AUTOSAR XML (schema 00048)
standard types defined: Boolean, SInt8, UInt16, UInt32, UInt8, boolean, uint16, uint32, uint8, sint8
package /AppNvM_SR_pkg/AppNvM_SR_dt
  11 x impl type, all with category=ARRAY:
    rt_Array_SInt8_160
      element rt_Array_SInt8_160: array-size=160, array-size-semantics=FIXED-SIZE, implementation-data-type=SInt8
    rt_Array_UInt8_128
      element rt_Array_UInt8_128: array-size=128, array-size-semantics=FIXED-SIZE, implementation-data-type=AppNvM_SR_dt/UInt8
    rt_Array_UInt8_16
      element rt_Array_UInt8_16: array-size=16, array-size-semantics=FIXED-SIZE, implementation-data-type=AppNvM_SR_dt/UInt8
    rt_Array_UInt8_17
      element rt_Array_UInt8_17: array-size=17, array-size-semantics=FIXED-SIZE, implementation-data-type=AppNvM_SR_dt/UInt8
    rt_Array_UInt8_18
      element rt_Array_UInt8_18: array-size=18, array-size-semantics=FIXED-SIZE, implementation-data-type=AppNvM_SR_dt/UInt8
    rt_Array_UInt8_240
      element rt_Array_UInt8_240: array-size=240, array-size-semantics=FIXED-SIZE, implementation-data-type=AppNvM_SR_dt/UInt8
    rt_Array_UInt8_3
      element rt_Array_UInt8_3: array-size=3, array-size-semantics=FIXED-SIZE, implementation-data-type=AppNvM_SR_dt/UInt8
    rt_Array_UInt8_4
      element rt_Array_UInt8_4: array-size=4, array-size-semantics=FIXED-SIZE, implementation-data-type=AppNvM_SR_dt/UInt8
    rt_Array_UInt8_50
      element rt_Array_UInt8_50: array-size=50, array-size-semantics=FIXED-SIZE, implementation-data-type=AppNvM_SR_dt/UInt8
    rt_Array_UInt8_6
      element rt_Array_UInt8_6: array-size=6, array-size-semantics=FIXED-SIZE, implementation-data-type=AppNvM_SR_dt/UInt8
    rt_Array_UInt8_8
      element rt_Array_UInt8_8: array-size=8, array-size-semantics=FIXED-SIZE, implementation-data-type=AppNvM_SR_dt/UInt8
package /AppNvM_SR_pkg/AppNvM_SR_if
  94 x sender receiver interface:
    gAppDiag_1809: invalidation-policy{data-element=gAppDiag_1809/Val, handle-invalid=DONT-INVALIDATE}
      data Val: sw-calibration-access=READ-ONLY, type=rt_Array_UInt8_16
    gAppDiag_1809Cnt: invalidation-policy{data-element=gAppDiag_1809Cnt/Val, handle-invalid=DONT-INVALIDATE}
      data Val: sw-calibration-access=READ-ONLY, type=AppNvM_SR_dt/UInt8
    gAppDiag_1A08: invalidation-policy{data-element=gAppDiag_1A08/Val, handle-invalid=DONT-INVALIDATE}
      data Val: type=rt_Array_UInt8_8
    gAppDiag_1A08Cnt: invalidation-policy{data-element=gAppDiag_1A08Cnt/Val, handle-invalid=DONT-INVALIDATE}
      data Val: type=AppNvM_SR_dt/UInt8
    gAppDiag_2006: invalidation-policy{data-element=gAppDiag_2006/Val, handle-invalid=DONT-INVALIDATE}
      data Val: type=rt_Array_UInt8_16
    gAppDiag_2006Cnt: invalidation-policy{data-element=gAppDiag_2006Cnt/Val, handle-invalid=DONT-INVALIDATE}
      data Val: type=AppNvM_SR_dt/UInt8
    gAppDiag_220C: invalidation-policy{data-element=gAppDiag_220C/Val, handle-invalid=DONT-INVALIDATE}
      data Val: type=rt_Array_UInt8_8
    gAppDiag_220CCnt: invalidation-policy{data-element=gAppDiag_220CCnt/Val, handle-invalid=DONT-INVALIDATE}
      data Val: type=AppNvM_SR_dt/UInt8
    gAppDiag_3206: invalidation-policy{data-element=gAppDiag_3206/Val, handle-invalid=DONT-INVALIDATE}
      data Val: sw-calibration-access=READ-ONLY, type=rt_Array_UInt8_50
    gAppDiag_3206Cnt: invalidation-policy{data-element=gAppDiag_3206Cnt/Val, handle-invalid=DONT-INVALIDATE}
      data Val: sw-calibration-access=READ-ONLY, type=AppNvM_SR_dt/UInt8
    gAppDiag_3207: invalidation-policy{data-element=gAppDiag_3207/Val, handle-invalid=DONT-INVALIDATE}
      data Val: sw-calibration-access=READ-ONLY, type=rt_Array_UInt8_50
    gAppDiag_3207Cnt: invalidation-policy{data-element=gAppDiag_3207Cnt/Val, handle-invalid=DONT-INVALIDATE}
      data Val: sw-calibration-access=READ-ONLY, type=AppNvM_SR_dt/UInt8
    gAppDiag_600A: invalidation-policy{data-element=gAppDiag_600A/Val, handle-invalid=DONT-INVALIDATE}
      data Val: type=rt_Array_UInt8_4
    gAppDiag_600ACnt: invalidation-policy{data-element=gAppDiag_600ACnt/Val, handle-invalid=DONT-INVALIDATE}
      data Val: type=AppNvM_SR_dt/UInt8
    gAppDiag_600C: invalidation-policy{data-element=gAppDiag_600C/Val, handle-invalid=DONT-INVALIDATE}
      data Val: type=AppNvM_SR_dt/UInt8
    gAppDiag_600CCnt: invalidation-policy{data-element=gAppDiag_600CCnt/Val, handle-invalid=DONT-INVALIDATE}
      data Val: type=AppNvM_SR_dt/UInt8
    gAppDiag_C300: invalidation-policy{data-element=gAppDiag_C300/Val, handle-invalid=DONT-INVALIDATE}
      data Val: sw-calibration-access=READ-ONLY, type=rt_Array_UInt8_16
    gAppDiag_C300Cnt: invalidation-policy{data-element=gAppDiag_C300Cnt/Val, handle-invalid=DONT-INVALIDATE}
      data Val: sw-calibration-access=READ-ONLY, type=AppNvM_SR_dt/UInt8
    gAppDiag_F190: invalidation-policy{data-element=gAppDiag_F190/Val, handle-invalid=DONT-INVALIDATE}
      data Val: type=rt_Array_UInt8_17
    gAppDiag_F190Cnt: invalidation-policy{data-element=gAppDiag_F190Cnt/Val, handle-invalid=DONT-INVALIDATE}
      data Val: type=AppNvM_SR_dt/UInt8
    gAppDiag_F19A: invalidation-policy{data-element=gAppDiag_F19A/Val, handle-invalid=DONT-INVALIDATE}
      data Val: sw-calibration-access=READ-ONLY, type=AppNvM_SR_dt/UInt8
    gAppDiag_F19ACnt: invalidation-policy{data-element=gAppDiag_F19ACnt/Val, handle-invalid=DONT-INVALIDATE}
      data Val: sw-calibration-access=READ-ONLY, type=AppNvM_SR_dt/UInt8
    gAppNvM_1009: invalidation-policy{data-element=gAppNvM_1009/Val, handle-invalid=DONT-INVALIDATE}
      data Val: type=AppNvM_SR_dt/rt_Array_UInt8_6
    gAppNvM_1809: invalidation-policy{data-element=gAppNvM_1809/Val, handle-invalid=DONT-INVALIDATE}
      data Val: sw-calibration-access=READ-ONLY, type=rt_Array_UInt8_16
    gAppNvM_1A08: invalidation-policy{data-element=gAppNvM_1A08/Val, handle-invalid=DONT-INVALIDATE}
      data Val: type=rt_Array_UInt8_8
    gAppNvM_2006: invalidation-policy{data-element=gAppNvM_2006/Val, handle-invalid=DONT-INVALIDATE}
      data Val: type=rt_Array_UInt8_16
    gAppNvM_220C: invalidation-policy{data-element=gAppNvM_220C/Val, handle-invalid=DONT-INVALIDATE}
      data Val: type=rt_Array_UInt8_8
    gAppNvM_3206: invalidation-policy{data-element=gAppNvM_3206/Val, handle-invalid=DONT-INVALIDATE}
      data Val: sw-calibration-access=READ-ONLY, type=rt_Array_UInt8_50
    gAppNvM_3207: invalidation-policy{data-element=gAppNvM_3207/Val, handle-invalid=DONT-INVALIDATE}
      data Val: sw-calibration-access=READ-ONLY, type=rt_Array_UInt8_50
    gAppNvM_600A: invalidation-policy{data-element=gAppNvM_600A/Val, handle-invalid=DONT-INVALIDATE}
      data Val: type=rt_Array_UInt8_4
    gAppNvM_600C: invalidation-policy{data-element=gAppNvM_600C/Val, handle-invalid=DONT-INVALIDATE}
      data Val: type=AppNvM_SR_dt/UInt8
    gAppNvM_C300: invalidation-policy{data-element=gAppNvM_C300/Val, handle-invalid=DONT-INVALIDATE}
      data Val: sw-calibration-access=READ-ONLY, type=rt_Array_UInt8_16
    gAppNvM_F190: invalidation-policy{data-element=gAppNvM_F190/Val, handle-invalid=DONT-INVALIDATE}
      data Val: type=rt_Array_UInt8_17
    gAppNvM_F19A: invalidation-policy{data-element=gAppNvM_F19A/Val, handle-invalid=DONT-INVALIDATE}
      data Val: sw-calibration-access=READ-ONLY, type=AppNvM_SR_dt/UInt8
    gEDH_u16RLDoorHandleBigPosition: invalidation-policy{data-element=gEDH_u16RLDoorHandleBigPosition/Val, handle-invalid=DONT-INVALIDATE}
      data Val: sw-calibration-access=READ-ONLY, type=UInt16
    gEDH_u16RLDoorHandlePosition: invalidation-policy{data-element=gEDH_u16RLDoorHandlePosition/Val, handle-invalid=DONT-INVALIDATE}
      data Val: sw-calibration-access=READ-ONLY, type=UInt16
    gEDH_u16RLDoorHandleSmallPosition: invalidation-policy{data-element=gEDH_u16RLDoorHandleSmallPosition/Val, handle-invalid=DONT-INVALIDATE}
      data Val: sw-calibration-access=READ-ONLY, type=UInt16
    gEDH_u16RRDoorHandleBigPosition: invalidation-policy{data-element=gEDH_u16RRDoorHandleBigPosition/Val, handle-invalid=DONT-INVALIDATE}
      data Val: sw-calibration-access=READ-ONLY, type=UInt16
    gEDH_u16RRDoorHandlePosition: invalidation-policy{data-element=gEDH_u16RRDoorHandlePosition/Val, handle-invalid=DONT-INVALIDATE}
      data Val: sw-calibration-access=READ-ONLY, type=UInt16
    gEDH_u16RRDoorHandleSmallPosition: invalidation-policy{data-element=gEDH_u16RRDoorHandleSmallPosition/Val, handle-invalid=DONT-INVALIDATE}
      data Val: sw-calibration-access=READ-ONLY, type=UInt16
    gEDH_u8RLDoorHandleBigPositionWrtCnt: invalidation-policy{data-element=gEDH_u8RLDoorHandleBigPositionWrtCnt/Val, handle-invalid=DONT-INVALIDATE}
      data Val: sw-calibration-access=READ-ONLY, type=AppNvM_SR_dt/UInt8
    gEDH_u8RLDoorHandlePositionWrtCnt: invalidation-policy{data-element=gEDH_u8RLDoorHandlePositionWrtCnt/Val, handle-invalid=DONT-INVALIDATE}
      data Val: sw-calibration-access=READ-ONLY, type=AppNvM_SR_dt/UInt8
    gEDH_u8RLDoorHandleSmallPositionWrtCnt: invalidation-policy{data-element=gEDH_u8RLDoorHandleSmallPositionWrtCnt/Val, handle-invalid=DONT-INVALIDATE}
      data Val: sw-calibration-access=READ-ONLY, type=AppNvM_SR_dt/UInt8
    gEDH_u8RRDoorHandleBigPositionWrtCnt: invalidation-policy{data-element=gEDH_u8RRDoorHandleBigPositionWrtCnt/Val, handle-invalid=DONT-INVALIDATE}
      data Val: sw-calibration-access=READ-ONLY, type=AppNvM_SR_dt/UInt8
    gEDH_u8RRDoorHandlePositionWrtCnt: invalidation-policy{data-element=gEDH_u8RRDoorHandlePositionWrtCnt/Val, handle-invalid=DONT-INVALIDATE}
      data Val: sw-calibration-access=READ-ONLY, type=AppNvM_SR_dt/UInt8
    gEDH_u8RRDoorHandleSmallPositionWrtCnt: invalidation-policy{data-element=gEDH_u8RRDoorHandleSmallPositionWrtCnt/Val, handle-invalid=DONT-INVALIDATE}
      data Val: sw-calibration-access=READ-ONLY, type=AppNvM_SR_dt/UInt8
    gEPB_u8PbcoutDataStorageArea1WrtCnt: invalidation-policy{data-element=gEPB_u8PbcoutDataStorageArea1WrtCnt/Val, handle-invalid=DONT-INVALIDATE}
      data Val: sw-calibration-access=READ-ONLY, type=AppNvM_SR_dt/UInt8
    gEPB_u8PbcoutDataStorageArea2WrtCnt: invalidation-policy{data-element=gEPB_u8PbcoutDataStorageArea2WrtCnt/Val, handle-invalid=DONT-INVALIDATE}
      data Val: sw-calibration-access=READ-ONLY, type=AppNvM_SR_dt/UInt8
    gEPB_u8PbcoutDataStorageArea3WrtCnt: invalidation-policy{data-element=gEPB_u8PbcoutDataStorageArea3WrtCnt/Val, handle-invalid=DONT-INVALIDATE}
      data Val: sw-calibration-access=READ-ONLY, type=AppNvM_SR_dt/UInt8
    gEPB_u8PbcoutDataStorageWriteArea1_a: invalidation-policy{data-element=gEPB_u8PbcoutDataStorageWriteArea1_a/Val, handle-invalid=DONT-INVALIDATE}
      data Val: sw-calibration-access=READ-ONLY, type=rt_Array_UInt8_8
    gEPB_u8PbcoutDataStorageWriteArea2_a: invalidation-policy{data-element=gEPB_u8PbcoutDataStorageWriteArea2_a/Val, handle-invalid=DONT-INVALIDATE}
      data Val: sw-calibration-access=READ-ONLY, type=rt_Array_UInt8_8
    gEPB_u8PbcoutDataStorageWriteArea3_a: invalidation-policy{data-element=gEPB_u8PbcoutDataStorageWriteArea3_a/Val, handle-invalid=DONT-INVALIDATE}
      data Val: sw-calibration-access=READ-ONLY, type=rt_Array_UInt8_240
    gEPB_u8SsmoutDataStorageWrite_a: invalidation-policy{data-element=gEPB_u8SsmoutDataStorageWrite_a/Val, handle-invalid=DONT-INVALIDATE}
      data Val: sw-calibration-access=READ-ONLY, type=rt_Array_UInt8_128
    gEPB_u8SsmoutDataStorageWrtCnt: invalidation-policy{data-element=gEPB_u8SsmoutDataStorageWrtCnt/Val, handle-invalid=DONT-INVALIDATE}
      data Val: sw-calibration-access=READ-ONLY, type=AppNvM_SR_dt/UInt8
    gNVM_au8SlcEepBlock_RR: invalidation-policy{data-element=gNVM_au8SlcEepBlock_RR/Val, handle-invalid=DONT-INVALIDATE}
      data Val: type=rt_Array_SInt8_160
    gNVM_au8SlcEepBlock2_RR: invalidation-policy{data-element=gNVM_au8SlcEepBlock2_RR/Val, handle-invalid=DONT-INVALIDATE}
      data Val: type=rt_Array_UInt8_18
    gNVM_bPbcinDataStorageValid1: invalidation-policy{data-element=gNVM_bPbcinDataStorageValid1/Val, handle-invalid=DONT-INVALIDATE}
      data Val: sw-calibration-access=READ-ONLY, type=Boolean
    gNVM_bPbcinDataStorageValid2: invalidation-policy{data-element=gNVM_bPbcinDataStorageValid2/Val, handle-invalid=DONT-INVALIDATE}
      data Val: sw-calibration-access=READ-ONLY, type=Boolean
    gNVM_bPbcinDataStorageValid3: invalidation-policy{data-element=gNVM_bPbcinDataStorageValid3/Val, handle-invalid=DONT-INVALIDATE}
      data Val: sw-calibration-access=READ-ONLY, type=Boolean
    gNVM_bRLTPflg: invalidation-policy{data-element=gNVM_bRLTPflg/Val, handle-invalid=DONT-INVALIDATE}
      data Val: type=Boolean
    gNVM_bRRTPflg: invalidation-policy{data-element=gNVM_bRRTPflg/Val, handle-invalid=DONT-INVALIDATE}
      data Val: type=Boolean
    gNVM_bSsminDataStorageValid: invalidation-policy{data-element=gNVM_bSsminDataStorageValid/Val, handle-invalid=DONT-INVALIDATE}
      data Val: sw-calibration-access=READ-ONLY, type=Boolean
    gNVM_s8SlcEepBlock_FRL: invalidation-policy{data-element=gNVM_s8SlcEepBlock_FRL/Val, handle-invalid=DONT-INVALIDATE}
      data Val: type=rt_Array_SInt8_160
    gNVM_u16RLDoorHandleBigPosition: invalidation-policy{data-element=gNVM_u16RLDoorHandleBigPosition/Val, handle-invalid=DONT-INVALIDATE}
      data Val: sw-calibration-access=READ-ONLY, type=UInt16
    gNVM_u16RLDoorHandlePosition: invalidation-policy{data-element=gNVM_u16RLDoorHandlePosition/Val, handle-invalid=DONT-INVALIDATE}
      data Val: sw-calibration-access=READ-ONLY, type=UInt16
    gNVM_u16RLDoorHandleSmallPosition: invalidation-policy{data-element=gNVM_u16RLDoorHandleSmallPosition/Val, handle-invalid=DONT-INVALIDATE}
      data Val: sw-calibration-access=READ-ONLY, type=UInt16
    gNVM_u16RRDoorHandleBigPosition: invalidation-policy{data-element=gNVM_u16RRDoorHandleBigPosition/Val, handle-invalid=DONT-INVALIDATE}
      data Val: sw-calibration-access=READ-ONLY, type=UInt16
    gNVM_u16RRDoorHandlePosition: invalidation-policy{data-element=gNVM_u16RRDoorHandlePosition/Val, handle-invalid=DONT-INVALIDATE}
      data Val: sw-calibration-access=READ-ONLY, type=UInt16
    gNVM_u16RRDoorHandleSmallPosition: invalidation-policy{data-element=gNVM_u16RRDoorHandleSmallPosition/Val, handle-invalid=DONT-INVALIDATE}
      data Val: sw-calibration-access=READ-ONLY, type=UInt16
    gNVM_u32RLMotorTemperature: invalidation-policy{data-element=gNVM_u32RLMotorTemperature/Val, handle-invalid=DONT-INVALIDATE}
      data Val: type=UInt32
    gNVM_u32RRMotorTemperature: invalidation-policy{data-element=gNVM_u32RRMotorTemperature/Val, handle-invalid=DONT-INVALIDATE}
      data Val: type=UInt32
    gNVM_u8FvMTripCntBlock: invalidation-policy{data-element=gNVM_u8FvMTripCntBlock/Val, handle-invalid=DONT-INVALIDATE}
      data Val: type=rt_Array_UInt8_4
    gNVM_u8PbcinDataStorageReadArea1_a: invalidation-policy{data-element=gNVM_u8PbcinDataStorageReadArea1_a/Val, handle-invalid=DONT-INVALIDATE}
      data Val: sw-calibration-access=READ-ONLY, type=rt_Array_UInt8_8
    gNVM_u8PbcinDataStorageReadArea2_a: invalidation-policy{data-element=gNVM_u8PbcinDataStorageReadArea2_a/Val, handle-invalid=DONT-INVALIDATE}
      data Val: sw-calibration-access=READ-ONLY, type=rt_Array_UInt8_8
    gNVM_u8PbcinDataStorageReadArea3_a: invalidation-policy{data-element=gNVM_u8PbcinDataStorageReadArea3_a/Val, handle-invalid=DONT-INVALIDATE}
      data Val: sw-calibration-access=READ-ONLY, type=rt_Array_UInt8_240
    gNVM_u8SecOCBlock: invalidation-policy{data-element=gNVM_u8SecOCBlock/Val, handle-invalid=DONT-INVALIDATE}
      data Val: type=rt_Array_UInt8_3
    gNVM_u8SlcEepBlock2_FRL: invalidation-policy{data-element=gNVM_u8SlcEepBlock2_FRL/Val, handle-invalid=DONT-INVALIDATE}
      data Val: type=rt_Array_UInt8_18
    gNVM_u8SsminDataStorageRead_a: invalidation-policy{data-element=gNVM_u8SsminDataStorageRead_a/Val, handle-invalid=DONT-INVALIDATE}
      data Val: sw-calibration-access=READ-ONLY, type=rt_Array_UInt8_128
    gSLC_s8SlcEepBlock_FRL: invalidation-policy{data-element=gSLC_s8SlcEepBlock_FRL/Val, handle-invalid=DONT-INVALIDATE}
      data Val: type=rt_Array_SInt8_160
    gSLC_s8SlcEepBlock_RR: invalidation-policy{data-element=gSLC_s8SlcEepBlock_RR/Val, handle-invalid=DONT-INVALIDATE}
      data Val: type=rt_Array_SInt8_160
    gSLC_u8FRLEEWrtCnt: invalidation-policy{data-element=gSLC_u8FRLEEWrtCnt/Val, handle-invalid=DONT-INVALIDATE}
      data Val: type=AppNvM_SR_dt/UInt8
    gSLC_u8FRLEEWrtCnt2: invalidation-policy{data-element=gSLC_u8FRLEEWrtCnt2/Val, handle-invalid=DONT-INVALIDATE}
      data Val: type=AppNvM_SR_dt/UInt8
    gSLC_u8RREEWrtCnt: invalidation-policy{data-element=gSLC_u8RREEWrtCnt/Val, handle-invalid=DONT-INVALIDATE}
      data Val: type=AppNvM_SR_dt/UInt8
    gSLC_u8RREEWrtCnt2: invalidation-policy{data-element=gSLC_u8RREEWrtCnt2/Val, handle-invalid=DONT-INVALIDATE}
      data Val: type=AppNvM_SR_dt/UInt8
    gSLC_u8SlcEepBlock2_FRL: invalidation-policy{data-element=gSLC_u8SlcEepBlock2_FRL/Val, handle-invalid=DONT-INVALIDATE}
      data Val: type=rt_Array_UInt8_18
    gSLC_u8SlcEepBlock2_RR: invalidation-policy{data-element=gSLC_u8SlcEepBlock2_RR/Val, handle-invalid=DONT-INVALIDATE}
      data Val: type=rt_Array_UInt8_18
    gUxFvM_u8FvMTripCntBlock: invalidation-policy{data-element=gUxFvM_u8FvMTripCntBlock/Val, handle-invalid=DONT-INVALIDATE}
      data Val: type=rt_Array_UInt8_4
    gUxFvM_u8FvMTripCntBlockWrtCnt: invalidation-policy{data-element=gUxFvM_u8FvMTripCntBlockWrtCnt/Val, handle-invalid=DONT-INVALIDATE}
      data Val: type=AppNvM_SR_dt/UInt8
    gUxSecOC_u8SecOCBlock: invalidation-policy{data-element=gUxSecOC_u8SecOCBlock/Val, handle-invalid=DONT-INVALIDATE}
      data Val: type=rt_Array_UInt8_3
    gUxSecOC_u8SecOCBlockWrtCnt: invalidation-policy{data-element=gUxSecOC_u8SecOCBlockWrtCnt/Val, handle-invalid=DONT-INVALIDATE}
      data Val: type=AppNvM_SR_dt/UInt8
    gWND_bRLTPflg: invalidation-policy{data-element=gWND_bRLTPflg/Val, handle-invalid=DONT-INVALIDATE}
      data Val: type=Boolean
    gWND_bRRTPflg: invalidation-policy{data-element=gWND_bRRTPflg/Val, handle-invalid=DONT-INVALIDATE}
      data Val: type=Boolean
    gWND_u32RLMotorTemperature: invalidation-policy{data-element=gWND_u32RLMotorTemperature/Val, handle-invalid=DONT-INVALIDATE}
      data Val: type=UInt32
    gWND_u32RRMotorTemperature: invalidation-policy{data-element=gWND_u32RRMotorTemperature/Val, handle-invalid=DONT-INVALIDATE}
      data Val: type=UInt32
package /AppNvM_SR_pkg/AppNvM_SR_swc
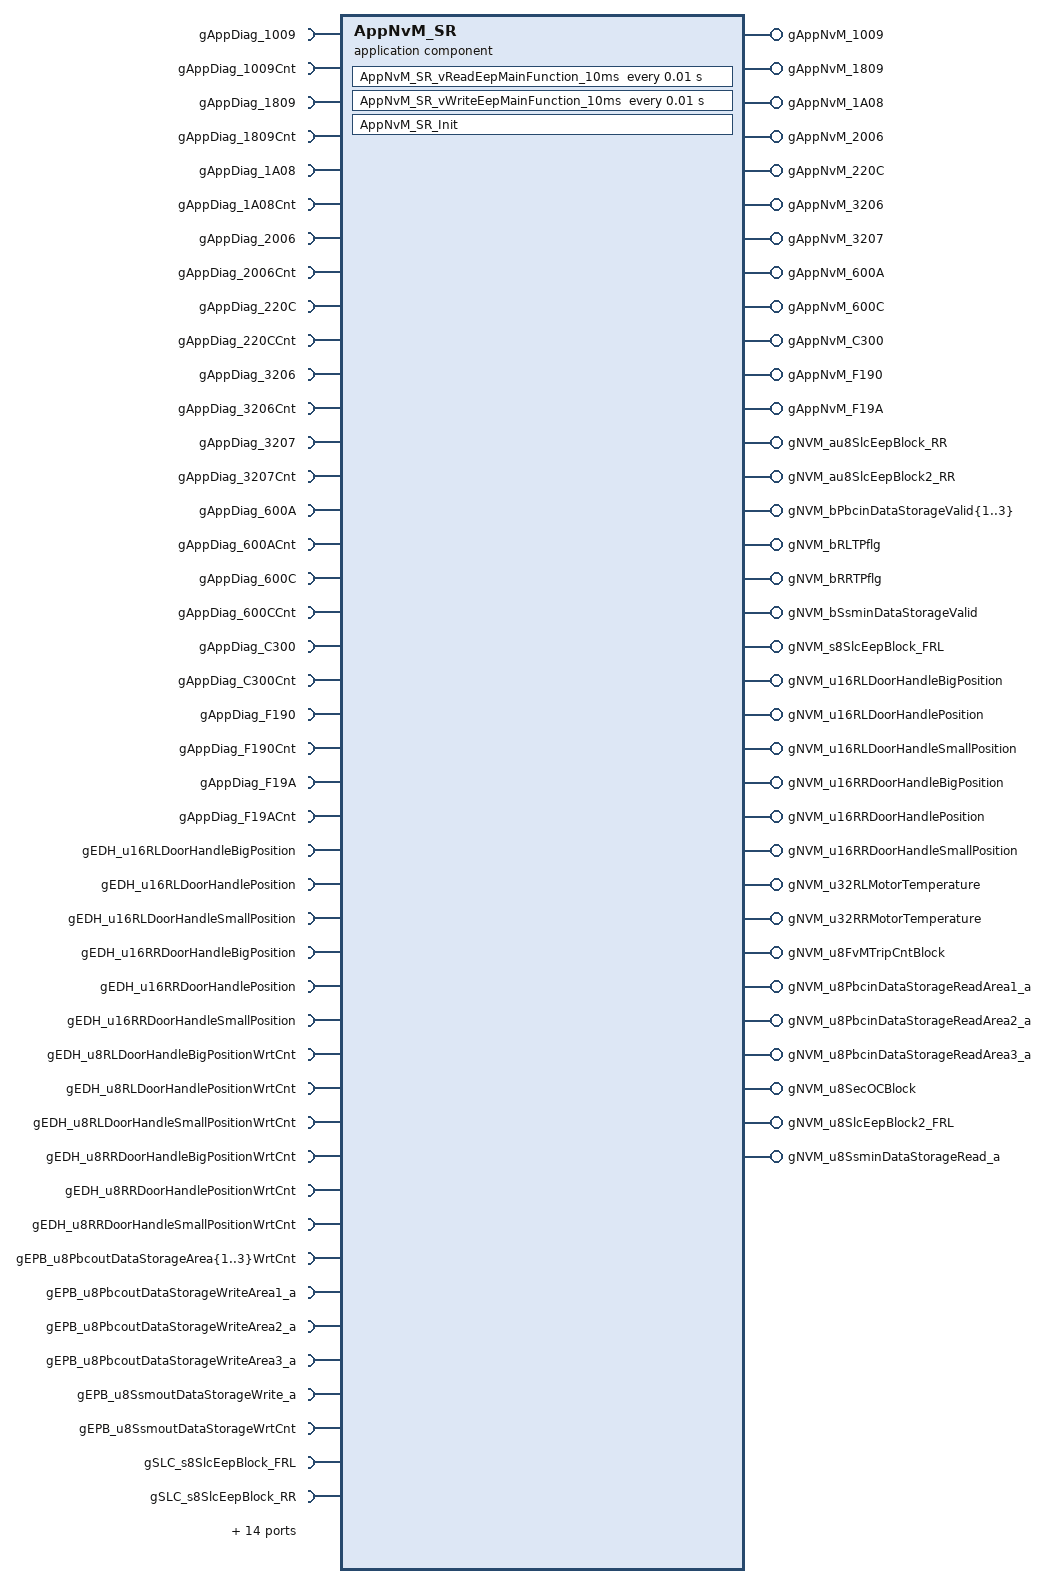
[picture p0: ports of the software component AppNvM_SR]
  application sw component type AppNvM_SR
    36 x provide port:
      gAppNvM_1009: nonqueued-sender-com-spec{data-element=gAppNvM_1009/Val, init-value=6 x 0}, provided-interface=gAppNvM_1009
      gAppNvM_1809: nonqueued-sender-com-spec{data-element=gAppNvM_1809/Val, init-value=16 x 0}, provided-interface=gAppNvM_1809
      gAppNvM_1A08: nonqueued-sender-com-spec{data-element=gAppNvM_1A08/Val, init-value=8 x 0}, provided-interface=gAppNvM_1A08
      gAppNvM_2006: nonqueued-sender-com-spec{data-element=gAppNvM_2006/Val, init-value=16 x 0}, provided-interface=gAppNvM_2006
      gAppNvM_220C: nonqueued-sender-com-spec{data-element=gAppNvM_220C/Val, init-value=8 x 0}, provided-interface=gAppNvM_220C
      gAppNvM_3206: nonqueued-sender-com-spec{data-element=gAppNvM_3206/Val, init-value=50 x 0}, provided-interface=gAppNvM_3206
      gAppNvM_3207: nonqueued-sender-com-spec{data-element=gAppNvM_3207/Val, init-value=50 x 0}, provided-interface=gAppNvM_3207
      gAppNvM_600A: nonqueued-sender-com-spec{data-element=gAppNvM_600A/Val, init-value=[0, 0, 0, 0]}, provided-interface=gAppNvM_600A
      gAppNvM_600C: nonqueued-sender-com-spec{data-element=gAppNvM_600C/Val, init-value=0}, provided-interface=gAppNvM_600C
      gAppNvM_C300: nonqueued-sender-com-spec{data-element=gAppNvM_C300/Val, init-value=16 x 0}, provided-interface=gAppNvM_C300
      gAppNvM_F190: nonqueued-sender-com-spec{data-element=gAppNvM_F190/Val, init-value=17 x 0}, provided-interface=gAppNvM_F190
      gAppNvM_F19A: nonqueued-sender-com-spec{data-element=gAppNvM_F19A/Val, init-value=0}, provided-interface=gAppNvM_F19A
      gNVM_au8SlcEepBlock_RR: nonqueued-sender-com-spec{data-element=gNVM_au8SlcEepBlock_RR/Val, init-value=160 x 0}, provided-interface=gNVM_au8SlcEepBlock_RR
      gNVM_au8SlcEepBlock2_RR: nonqueued-sender-com-spec{data-element=gNVM_au8SlcEepBlock2_RR/Val, init-value=18 x 0}, provided-interface=gNVM_au8SlcEepBlock2_RR
      gNVM_bPbcinDataStorageValid{1..3}: nonqueued-sender-com-spec{data-element=gNVM_bPbcinDataStorageValid{1..3}/Val, init-value=0}, provided-interface=gNVM_bPbcinDataStorageValid{1..3}
      gNVM_bRLTPflg: nonqueued-sender-com-spec{data-element=gNVM_bRLTPflg/Val, init-value=0}, provided-interface=gNVM_bRLTPflg
      gNVM_bRRTPflg: nonqueued-sender-com-spec{data-element=gNVM_bRRTPflg/Val, init-value=0}, provided-interface=gNVM_bRRTPflg
      gNVM_bSsminDataStorageValid: nonqueued-sender-com-spec{data-element=gNVM_bSsminDataStorageValid/Val, init-value=0}, provided-interface=gNVM_bSsminDataStorageValid
      gNVM_s8SlcEepBlock_FRL: nonqueued-sender-com-spec{data-element=gNVM_s8SlcEepBlock_FRL/Val, init-value=160 x 0}, provided-interface=gNVM_s8SlcEepBlock_FRL
      gNVM_u16RLDoorHandleBigPosition: nonqueued-sender-com-spec{data-element=gNVM_u16RLDoorHandleBigPosition/Val, init-value=65535}, provided-interface=gNVM_u16RLDoorHandleBigPosition
      gNVM_u16RLDoorHandlePosition: nonqueued-sender-com-spec{data-element=gNVM_u16RLDoorHandlePosition/Val, init-value=32767}, provided-interface=gNVM_u16RLDoorHandlePosition
      gNVM_u16RLDoorHandleSmallPosition: nonqueued-sender-com-spec{data-element=gNVM_u16RLDoorHandleSmallPosition/Val, init-value=0}, provided-interface=gNVM_u16RLDoorHandleSmallPosition
      gNVM_u16RRDoorHandleBigPosition: nonqueued-sender-com-spec{data-element=gNVM_u16RRDoorHandleBigPosition/Val, init-value=65535}, provided-interface=gNVM_u16RRDoorHandleBigPosition
      gNVM_u16RRDoorHandlePosition: nonqueued-sender-com-spec{data-element=gNVM_u16RRDoorHandlePosition/Val, init-value=32767}, provided-interface=gNVM_u16RRDoorHandlePosition
      gNVM_u16RRDoorHandleSmallPosition: nonqueued-sender-com-spec{data-element=gNVM_u16RRDoorHandleSmallPosition/Val, init-value=0}, provided-interface=gNVM_u16RRDoorHandleSmallPosition
      gNVM_u32RLMotorTemperature: nonqueued-sender-com-spec{data-element=gNVM_u32RLMotorTemperature/Val, init-value=0}, provided-interface=gNVM_u32RLMotorTemperature
      gNVM_u32RRMotorTemperature: nonqueued-sender-com-spec{data-element=gNVM_u32RRMotorTemperature/Val, init-value=0}, provided-interface=gNVM_u32RRMotorTemperature
      gNVM_u8FvMTripCntBlock: nonqueued-sender-com-spec{data-element=gNVM_u8FvMTripCntBlock/Val, init-value=[0, 0, 0, 0]}, provided-interface=gNVM_u8FvMTripCntBlock
      gNVM_u8PbcinDataStorageReadArea1_a: nonqueued-sender-com-spec{data-element=gNVM_u8PbcinDataStorageReadArea1_a/Val, init-value=8 x 255}, provided-interface=gNVM_u8PbcinDataStorageReadArea1_a
      gNVM_u8PbcinDataStorageReadArea2_a: nonqueued-sender-com-spec{data-element=gNVM_u8PbcinDataStorageReadArea2_a/Val, init-value=8 x 255}, provided-interface=gNVM_u8PbcinDataStorageReadArea2_a
      gNVM_u8PbcinDataStorageReadArea3_a: nonqueued-sender-com-spec{data-element=gNVM_u8PbcinDataStorageReadArea3_a/Val, init-value=240 x 255}, provided-interface=gNVM_u8PbcinDataStorageReadArea3_a
      gNVM_u8SecOCBlock: nonqueued-sender-com-spec{data-element=gNVM_u8SecOCBlock/Val, init-value=[0, 0, 255]}, provided-interface=gNVM_u8SecOCBlock
      gNVM_u8SlcEepBlock2_FRL: nonqueued-sender-com-spec{data-element=gNVM_u8SlcEepBlock2_FRL/Val, init-value=18 x 0}, provided-interface=gNVM_u8SlcEepBlock2_FRL
      gNVM_u8SsminDataStorageRead_a: nonqueued-sender-com-spec{data-element=gNVM_u8SsminDataStorageRead_a/Val, init-value=128 x 255}, provided-interface=gNVM_u8SsminDataStorageRead_a
    60 x require port:
      gAppDiag_1009: nonqueued-receiver-com-spec{data-element=gAppDiag_1009/Val, filter=data-filter-type=ALWAYS, init-value=6 x 0}, required-interface=gAppDiag_1009
      gAppDiag_1009Cnt: nonqueued-receiver-com-spec{data-element=gAppDiag_1009Cnt/Val, filter=data-filter-type=ALWAYS, init-value=0}, required-interface=gAppDiag_1009Cnt
      gAppDiag_1809: nonqueued-receiver-com-spec{data-element=gAppDiag_1809/Val, filter=data-filter-type=ALWAYS, init-value=16 x 0}, required-interface=gAppDiag_1809
      gAppDiag_1809Cnt: nonqueued-receiver-com-spec{data-element=gAppDiag_1809Cnt/Val, filter=data-filter-type=ALWAYS, init-value=0}, required-interface=gAppDiag_1809Cnt
      gAppDiag_1A08: nonqueued-receiver-com-spec{data-element=gAppDiag_1A08/Val, filter=data-filter-type=ALWAYS, init-value=8 x 0}, required-interface=gAppDiag_1A08
      gAppDiag_1A08Cnt: nonqueued-receiver-com-spec{data-element=gAppDiag_1A08Cnt/Val, filter=data-filter-type=ALWAYS, init-value=0}, required-interface=gAppDiag_1A08Cnt
      gAppDiag_2006: nonqueued-receiver-com-spec{data-element=gAppDiag_2006/Val, filter=data-filter-type=ALWAYS, init-value=16 x 0}, required-interface=gAppDiag_2006
      gAppDiag_2006Cnt: nonqueued-receiver-com-spec{data-element=gAppDiag_2006Cnt/Val, filter=data-filter-type=ALWAYS, init-value=0}, required-interface=gAppDiag_2006Cnt
      gAppDiag_220C: nonqueued-receiver-com-spec{data-element=gAppDiag_220C/Val, filter=data-filter-type=ALWAYS, init-value=8 x 0}, required-interface=gAppDiag_220C
      gAppDiag_220CCnt: nonqueued-receiver-com-spec{data-element=gAppDiag_220CCnt/Val, filter=data-filter-type=ALWAYS, init-value=0}, required-interface=gAppDiag_220CCnt
      gAppDiag_3206: nonqueued-receiver-com-spec{data-element=gAppDiag_3206/Val, filter=data-filter-type=ALWAYS, init-value=50 x 0}, required-interface=gAppDiag_3206
      gAppDiag_3206Cnt: nonqueued-receiver-com-spec{data-element=gAppDiag_3206Cnt/Val, filter=data-filter-type=ALWAYS, init-value=0}, required-interface=gAppDiag_3206Cnt
      gAppDiag_3207: nonqueued-receiver-com-spec{data-element=gAppDiag_3207/Val, filter=data-filter-type=ALWAYS, init-value=50 x 0}, required-interface=gAppDiag_3207
      gAppDiag_3207Cnt: nonqueued-receiver-com-spec{data-element=gAppDiag_3207Cnt/Val, filter=data-filter-type=ALWAYS, init-value=0}, required-interface=gAppDiag_3207Cnt
      gAppDiag_600A: nonqueued-receiver-com-spec{data-element=gAppDiag_600A/Val, filter=data-filter-type=ALWAYS, init-value=[0, 0, 0, 0]}, required-interface=gAppDiag_600A
      gAppDiag_600ACnt: nonqueued-receiver-com-spec{data-element=gAppDiag_600ACnt/Val, filter=data-filter-type=ALWAYS, init-value=0}, required-interface=gAppDiag_600ACnt
      gAppDiag_600C: nonqueued-receiver-com-spec{data-element=gAppDiag_600C/Val, filter=data-filter-type=ALWAYS, init-value=0}, required-interface=gAppDiag_600C
      gAppDiag_600CCnt: nonqueued-receiver-com-spec{data-element=gAppDiag_600CCnt/Val, filter=data-filter-type=ALWAYS, init-value=0}, required-interface=gAppDiag_600CCnt
      gAppDiag_C300: nonqueued-receiver-com-spec{data-element=gAppDiag_C300/Val, filter=data-filter-type=ALWAYS, init-value=16 x 0}, required-interface=gAppDiag_C300
      gAppDiag_C300Cnt: nonqueued-receiver-com-spec{data-element=gAppDiag_C300Cnt/Val, filter=data-filter-type=ALWAYS, init-value=0}, required-interface=gAppDiag_C300Cnt
      gAppDiag_F190: nonqueued-receiver-com-spec{data-element=gAppDiag_F190/Val, filter=data-filter-type=ALWAYS, init-value=17 x 0}, required-interface=gAppDiag_F190
      gAppDiag_F190Cnt: nonqueued-receiver-com-spec{data-element=gAppDiag_F190Cnt/Val, filter=data-filter-type=ALWAYS, init-value=0}, required-interface=gAppDiag_F190Cnt
      gAppDiag_F19A: nonqueued-receiver-com-spec{data-element=gAppDiag_F19A/Val, filter=data-filter-type=ALWAYS, init-value=0}, required-interface=gAppDiag_F19A
      gAppDiag_F19ACnt: nonqueued-receiver-com-spec{data-element=gAppDiag_F19ACnt/Val, filter=data-filter-type=ALWAYS, init-value=0}, required-interface=gAppDiag_F19ACnt
      gEDH_u16RLDoorHandleBigPosition: nonqueued-receiver-com-spec{data-element=gEDH_u16RLDoorHandleBigPosition/Val, filter=data-filter-type=ALWAYS, init-value=0}, required-interface=gEDH_u16RLDoorHandleBigPosition
      gEDH_u16RLDoorHandlePosition: nonqueued-receiver-com-spec{data-element=gEDH_u16RLDoorHandlePosition/Val, filter=data-filter-type=ALWAYS, init-value=0}, required-interface=gEDH_u16RLDoorHandlePosition
      gEDH_u16RLDoorHandleSmallPosition: nonqueued-receiver-com-spec{data-element=gEDH_u16RLDoorHandleSmallPosition/Val, filter=data-filter-type=ALWAYS, init-value=0}, required-interface=gEDH_u16RLDoorHandleSmallPosition
      gEDH_u16RRDoorHandleBigPosition: nonqueued-receiver-com-spec{data-element=gEDH_u16RRDoorHandleBigPosition/Val, filter=data-filter-type=ALWAYS, init-value=0}, required-interface=gEDH_u16RRDoorHandleBigPosition
      gEDH_u16RRDoorHandlePosition: nonqueued-receiver-com-spec{data-element=gEDH_u16RRDoorHandlePosition/Val, filter=data-filter-type=ALWAYS, init-value=0}, required-interface=gEDH_u16RRDoorHandlePosition
      gEDH_u16RRDoorHandleSmallPosition: nonqueued-receiver-com-spec{data-element=gEDH_u16RRDoorHandleSmallPosition/Val, filter=data-filter-type=ALWAYS, init-value=0}, required-interface=gEDH_u16RRDoorHandleSmallPosition
      gEDH_u8RLDoorHandleBigPositionWrtCnt: nonqueued-receiver-com-spec{data-element=gEDH_u8RLDoorHandleBigPositionWrtCnt/Val, filter=data-filter-type=ALWAYS, init-value=0}, required-interface=gEDH_u8RLDoorHandleBigPositionWrtCnt
      gEDH_u8RLDoorHandlePositionWrtCnt: nonqueued-receiver-com-spec{data-element=gEDH_u8RLDoorHandlePositionWrtCnt/Val, filter=data-filter-type=ALWAYS, init-value=0}, required-interface=gEDH_u8RLDoorHandlePositionWrtCnt
      gEDH_u8RLDoorHandleSmallPositionWrtCnt: nonqueued-receiver-com-spec{data-element=gEDH_u8RLDoorHandleSmallPositionWrtCnt/Val, filter=data-filter-type=ALWAYS, init-value=0}, required-interface=gEDH_u8RLDoorHandleSmallPositionWrtCnt
      gEDH_u8RRDoorHandleBigPositionWrtCnt: nonqueued-receiver-com-spec{data-element=gEDH_u8RRDoorHandleBigPositionWrtCnt/Val, filter=data-filter-type=ALWAYS, init-value=0}, required-interface=gEDH_u8RRDoorHandleBigPositionWrtCnt
      gEDH_u8RRDoorHandlePositionWrtCnt: nonqueued-receiver-com-spec{data-element=gEDH_u8RRDoorHandlePositionWrtCnt/Val, filter=data-filter-type=ALWAYS, init-value=0}, required-interface=gEDH_u8RRDoorHandlePositionWrtCnt
      gEDH_u8RRDoorHandleSmallPositionWrtCnt: nonqueued-receiver-com-spec{data-element=gEDH_u8RRDoorHandleSmallPositionWrtCnt/Val, filter=data-filter-type=ALWAYS, init-value=0}, required-interface=gEDH_u8RRDoorHandleSmallPositionWrtCnt
      gEPB_u8PbcoutDataStorageArea{1..3}WrtCnt: nonqueued-receiver-com-spec{data-element=gEPB_u8PbcoutDataStorageArea{1..3}WrtCnt/Val, filter=data-filter-type=ALWAYS, init-value=0}, required-interface=gEPB_u8PbcoutDataStorageArea{1..3}WrtCnt
      gEPB_u8PbcoutDataStorageWriteArea1_a: nonqueued-receiver-com-spec{data-element=gEPB_u8PbcoutDataStorageWriteArea1_a/Val, filter=data-filter-type=ALWAYS, init-value=8 x 0}, required-interface=gEPB_u8PbcoutDataStorageWriteArea1_a
      gEPB_u8PbcoutDataStorageWriteArea2_a: nonqueued-receiver-com-spec{data-element=gEPB_u8PbcoutDataStorageWriteArea2_a/Val, filter=data-filter-type=ALWAYS, init-value=8 x 0}, required-interface=gEPB_u8PbcoutDataStorageWriteArea2_a
      gEPB_u8PbcoutDataStorageWriteArea3_a: nonqueued-receiver-com-spec{data-element=gEPB_u8PbcoutDataStorageWriteArea3_a/Val, filter=data-filter-type=ALWAYS, init-value=240 x 0}, required-interface=gEPB_u8PbcoutDataStorageWriteArea3_a
      gEPB_u8SsmoutDataStorageWrite_a: nonqueued-receiver-com-spec{data-element=gEPB_u8SsmoutDataStorageWrite_a/Val, filter=data-filter-type=ALWAYS, init-value=128 x 0}, required-interface=gEPB_u8SsmoutDataStorageWrite_a
      gEPB_u8SsmoutDataStorageWrtCnt: nonqueued-receiver-com-spec{data-element=gEPB_u8SsmoutDataStorageWrtCnt/Val, filter=data-filter-type=ALWAYS, init-value=0}, required-interface=gEPB_u8SsmoutDataStorageWrtCnt
      gSLC_s8SlcEepBlock_FRL: nonqueued-receiver-com-spec{data-element=gSLC_s8SlcEepBlock_FRL/Val, filter=data-filter-type=ALWAYS, init-value=160 x 0}, required-interface=gSLC_s8SlcEepBlock_FRL
      gSLC_s8SlcEepBlock_RR: nonqueued-receiver-com-spec{data-element=gSLC_s8SlcEepBlock_RR/Val, filter=data-filter-type=ALWAYS, init-value=160 x 0}, required-interface=gSLC_s8SlcEepBlock_RR
      gSLC_u8FRLEEWrtCnt: nonqueued-receiver-com-spec{data-element=gSLC_u8FRLEEWrtCnt/Val, filter=data-filter-type=ALWAYS, init-value=0}, required-interface=gSLC_u8FRLEEWrtCnt
      gSLC_u8FRLEEWrtCnt2: nonqueued-receiver-com-spec{data-element=gSLC_u8FRLEEWrtCnt2/Val, filter=data-filter-type=ALWAYS, init-value=0}, required-interface=gSLC_u8FRLEEWrtCnt2
      gSLC_u8RREEWrtCnt: nonqueued-receiver-com-spec{data-element=gSLC_u8RREEWrtCnt/Val, filter=data-filter-type=ALWAYS, init-value=0}, required-interface=gSLC_u8RREEWrtCnt
      gSLC_u8RREEWrtCnt2: nonqueued-receiver-com-spec{data-element=gSLC_u8RREEWrtCnt2/Val, filter=data-filter-type=ALWAYS, init-value=0}, required-interface=gSLC_u8RREEWrtCnt2
      gSLC_u8SlcEepBlock2_FRL: nonqueued-receiver-com-spec{data-element=gSLC_u8SlcEepBlock2_FRL/Val, filter=data-filter-type=ALWAYS, init-value=18 x 0}, required-interface=gSLC_u8SlcEepBlock2_FRL
      gSLC_u8SlcEepBlock2_RR: nonqueued-receiver-com-spec{data-element=gSLC_u8SlcEepBlock2_RR/Val, filter=data-filter-type=ALWAYS, init-value=18 x 0}, required-interface=gSLC_u8SlcEepBlock2_RR
      gUxFvM_u8FvMTripCntBlock: nonqueued-receiver-com-spec{data-element=gUxFvM_u8FvMTripCntBlock/Val, filter=data-filter-type=ALWAYS, init-value=[0, 0, 0, 0]}, required-interface=gUxFvM_u8FvMTripCntBlock
      gUxFvM_u8FvMTripCntBlockWrtCnt: nonqueued-receiver-com-spec{data-element=gUxFvM_u8FvMTripCntBlockWrtCnt/Val, filter=data-filter-type=ALWAYS, init-value=0}, required-interface=gUxFvM_u8FvMTripCntBlockWrtCnt
      gUxSecOC_u8SecOCBlock: nonqueued-receiver-com-spec{data-element=gUxSecOC_u8SecOCBlock/Val, filter=data-filter-type=ALWAYS, init-value=[0, 0, 0]}, required-interface=gUxSecOC_u8SecOCBlock
      gUxSecOC_u8SecOCBlockWrtCnt: nonqueued-receiver-com-spec{data-element=gUxSecOC_u8SecOCBlockWrtCnt/Val, filter=data-filter-type=ALWAYS, init-value=0}, required-interface=gUxSecOC_u8SecOCBlockWrtCnt
      gWND_bRLTPflg: nonqueued-receiver-com-spec{data-element=gWND_bRLTPflg/Val, filter=data-filter-type=ALWAYS, init-value=0}, required-interface=gWND_bRLTPflg
      gWND_bRRTPflg: nonqueued-receiver-com-spec{data-element=gWND_bRRTPflg/Val, filter=data-filter-type=ALWAYS, init-value=0}, required-interface=gWND_bRRTPflg
      gWND_u32RLMotorTemperature: nonqueued-receiver-com-spec{data-element=gWND_u32RLMotorTemperature/Val, filter=data-filter-type=ALWAYS, init-value=0}, required-interface=gWND_u32RLMotorTemperature
      gWND_u32RRMotorTemperature: nonqueued-receiver-com-spec{data-element=gWND_u32RRMotorTemperature/Val, filter=data-filter-type=ALWAYS, init-value=0}, required-interface=gWND_u32RRMotorTemperature
    behavior AppNvM_SR
      init event AppNvM_SR_InitEvent: start-on-event=AppNvM_SR_Init
      timing event TMT_AppNvM_SR_vReadEepMainFunction_10ms: start-on-event=AppNvM_SR_vReadEepMainFunction_10ms, period=0.01
      timing event TMT_AppNvM_SR_vWriteEepMainFunction_10ms: start-on-event=AppNvM_SR_vWriteEepMainFunction_10ms, period=0.01
      runnable AppNvM_SR_Init
      runnable AppNvM_SR_vReadEepMainFunction_10ms
        data-receive-point-by-arguments:
          60 x access:
            REC_gAppDiag_1009_Val: accessed-variable=gAppDiag_1009.Val
            REC_gAppDiag_1009Cnt_Val: accessed-variable=gAppDiag_1009Cnt.Val
            REC_gAppDiag_1809_Val: accessed-variable=gAppDiag_1809.Val
            REC_gAppDiag_1809Cnt_Val: accessed-variable=gAppDiag_1809Cnt.Val
            REC_gAppDiag_1A08_Val: accessed-variable=gAppDiag_1A08.Val
            REC_gAppDiag_1A08Cnt_Val: accessed-variable=gAppDiag_1A08Cnt.Val
            REC_gAppDiag_2006_Val: accessed-variable=gAppDiag_2006.Val
            REC_gAppDiag_2006Cnt_Val: accessed-variable=gAppDiag_2006Cnt.Val
            REC_gAppDiag_220C_Val: accessed-variable=gAppDiag_220C.Val
            REC_gAppDiag_220CCnt_Val: accessed-variable=gAppDiag_220CCnt.Val
            REC_gAppDiag_3206_Val: accessed-variable=gAppDiag_3206.Val
            REC_gAppDiag_3206Cnt_Val: accessed-variable=gAppDiag_3206Cnt.Val
            REC_gAppDiag_3207_Val: accessed-variable=gAppDiag_3207.Val
            REC_gAppDiag_3207Cnt_Val: accessed-variable=gAppDiag_3207Cnt.Val
            REC_gAppDiag_600A_Val: accessed-variable=gAppDiag_600A.Val
            REC_gAppDiag_600ACnt_Val: accessed-variable=gAppDiag_600ACnt.Val
            REC_gAppDiag_600C_Val: accessed-variable=gAppDiag_600C.Val
            REC_gAppDiag_600CCnt_Val: accessed-variable=gAppDiag_600CCnt.Val
            REC_gAppDiag_C300_Val: accessed-variable=gAppDiag_C300.Val
            REC_gAppDiag_C300Cnt_Val: accessed-variable=gAppDiag_C300Cnt.Val
            REC_gAppDiag_F190_Val: accessed-variable=gAppDiag_F190.Val
            REC_gAppDiag_F190Cnt_Val: accessed-variable=gAppDiag_F190Cnt.Val
            REC_gAppDiag_F19A_Val: accessed-variable=gAppDiag_F19A.Val
            REC_gAppDiag_F19ACnt_Val: accessed-variable=gAppDiag_F19ACnt.Val
            REC_gEDH_u16RLDoorHandleBigPosition_Val: accessed-variable=gEDH_u16RLDoorHandleBigPosition.Val
            REC_gEDH_u16RLDoorHandlePosition_Val: accessed-variable=gEDH_u16RLDoorHandlePosition.Val
            REC_gEDH_u16RLDoorHandleSmallPosition_Val: accessed-variable=gEDH_u16RLDoorHandleSmallPosition.Val
            REC_gEDH_u16RRDoorHandleBigPosition_Val: accessed-variable=gEDH_u16RRDoorHandleBigPosition.Val
            REC_gEDH_u16RRDoorHandlePosition_Val: accessed-variable=gEDH_u16RRDoorHandlePosition.Val
            REC_gEDH_u16RRDoorHandleSmallPosition_Val: accessed-variable=gEDH_u16RRDoorHandleSmallPosition.Val
            REC_gEDH_u8RLDoorHandleBigPositionWrtCnt_Val: accessed-variable=gEDH_u8RLDoorHandleBigPositionWrtCnt.Val
            REC_gEDH_u8RLDoorHandlePositionWrtCnt_Val: accessed-variable=gEDH_u8RLDoorHandlePositionWrtCnt.Val
            REC_gEDH_u8RLDoorHandleSmallPositionWrtCnt_Val: accessed-variable=gEDH_u8RLDoorHandleSmallPositionWrtCnt.Val
            REC_gEDH_u8RRDoorHandleBigPositionWrtCnt_Val: accessed-variable=gEDH_u8RRDoorHandleBigPositionWrtCnt.Val
            REC_gEDH_u8RRDoorHandlePositionWrtCnt_Val: accessed-variable=gEDH_u8RRDoorHandlePositionWrtCnt.Val
            REC_gEDH_u8RRDoorHandleSmallPositionWrtCnt_Val: accessed-variable=gEDH_u8RRDoorHandleSmallPositionWrtCnt.Val
            REC_gEPB_u8PbcoutDataStorageArea{1..3}WrtCnt_Val: accessed-variable=gEPB_u8PbcoutDataStorageArea{1..3}WrtCnt.Val
            REC_gEPB_u8PbcoutDataStorageWriteArea{1..3}_a_Val: accessed-variable=gEPB_u8PbcoutDataStorageWriteArea{1..3}_a.Val
            REC_gEPB_u8SsmoutDataStorageWrite_a_Val: accessed-variable=gEPB_u8SsmoutDataStorageWrite_a.Val
            REC_gEPB_u8SsmoutDataStorageWrtCnt_Val: accessed-variable=gEPB_u8SsmoutDataStorageWrtCnt.Val
            REC_gSLC_s8SlcEepBlock_FRL_Val: accessed-variable=gSLC_s8SlcEepBlock_FRL.Val
            REC_gSLC_s8SlcEepBlock_RR_Val: accessed-variable=gSLC_s8SlcEepBlock_RR.Val
            REC_gSLC_u8FRLEEWrtCnt_Val: accessed-variable=gSLC_u8FRLEEWrtCnt.Val
            REC_gSLC_u8FRLEEWrtCnt2_Val: accessed-variable=gSLC_u8FRLEEWrtCnt2.Val
            REC_gSLC_u8RREEWrtCnt_Val: accessed-variable=gSLC_u8RREEWrtCnt.Val
            REC_gSLC_u8RREEWrtCnt2_Val: accessed-variable=gSLC_u8RREEWrtCnt2.Val
            REC_gSLC_u8SlcEepBlock2_FRL_Val: accessed-variable=gSLC_u8SlcEepBlock2_FRL.Val
            REC_gSLC_u8SlcEepBlock2_RR_Val: accessed-variable=gSLC_u8SlcEepBlock2_RR.Val
            REC_gUxFvM_u8FvMTripCntBlock_Val: accessed-variable=gUxFvM_u8FvMTripCntBlock.Val
            REC_gUxFvM_u8FvMTripCntBlockWrtCnt_Val: accessed-variable=gUxFvM_u8FvMTripCntBlockWrtCnt.Val
            REC_gUxSecOC_u8SecOCBlock_Val: accessed-variable=gUxSecOC_u8SecOCBlock.Val
            REC_gUxSecOC_u8SecOCBlockWrtCnt_Val: accessed-variable=gUxSecOC_u8SecOCBlockWrtCnt.Val
            REC_gWND_bRLTPflg_Val: accessed-variable=gWND_bRLTPflg.Val
            REC_gWND_bRRTPflg_Val: accessed-variable=gWND_bRRTPflg.Val
            REC_gWND_u32RLMotorTemperature_Val: accessed-variable=gWND_u32RLMotorTemperature.Val
            REC_gWND_u32RRMotorTemperature_Val: accessed-variable=gWND_u32RRMotorTemperature.Val
      runnable AppNvM_SR_vWriteEepMainFunction_10ms
        data-send-points:
          33 x access:
            SEND_gAppNvM_1009_Val: accessed-variable=gAppNvM_1009.Val
            SEND_gAppNvM_1809_Val: accessed-variable=gAppNvM_1809.Val
            SEND_gAppNvM_1A08_Val: accessed-variable=gAppNvM_1A08.Val
            SEND_gAppNvM_2006_Val: accessed-variable=gAppNvM_2006.Val
            SEND_gAppNvM_220C_Val: accessed-variable=gAppNvM_220C.Val
            SEND_gAppNvM_3206_Val: accessed-variable=gAppNvM_3206.Val
            SEND_gAppNvM_3207_Val: accessed-variable=gAppNvM_3207.Val
            SEND_gAppNvM_600A_Val: accessed-variable=gAppNvM_600A.Val
            SEND_gAppNvM_600C_Val: accessed-variable=gAppNvM_600C.Val
            SEND_gAppNvM_C300_Val: accessed-variable=gAppNvM_C300.Val
            SEND_gAppNvM_F190_Val: accessed-variable=gAppNvM_F190.Val
            SEND_gAppNvM_F19A_Val: accessed-variable=gAppNvM_F19A.Val
            SEND_gNVM_bPbcinDataStorageValid{1..3}_Val: accessed-variable=gNVM_bPbcinDataStorageValid{1..3}.Val
            SEND_gNVM_bRLTPflg_Val: accessed-variable=gNVM_bRLTPflg.Val
            SEND_gNVM_bRRTPflg_Val: accessed-variable=gNVM_bRRTPflg.Val
            SEND_gNVM_bSsminDataStorageValid_Val: accessed-variable=gNVM_bSsminDataStorageValid.Val
            SEND_gNVM_s8SlcEepBlock_FRL_Val: accessed-variable=gNVM_s8SlcEepBlock_FRL.Val
            SEND_gNVM_u16RLDoorHandleBigPosition_Val: accessed-variable=gNVM_u16RLDoorHandleBigPosition.Val
            SEND_gNVM_u16RLDoorHandlePosition_Val: accessed-variable=gNVM_u16RLDoorHandlePosition.Val
            SEND_gNVM_u16RLDoorHandleSmallPosition_Val: accessed-variable=gNVM_u16RLDoorHandleSmallPosition.Val
            SEND_gNVM_u16RRDoorHandleBigPosition_Val: accessed-variable=gNVM_u16RRDoorHandleBigPosition.Val
            SEND_gNVM_u16RRDoorHandlePosition_Val: accessed-variable=gNVM_u16RRDoorHandlePosition.Val
            SEND_gNVM_u16RRDoorHandleSmallPosition_Val: accessed-variable=gNVM_u16RRDoorHandleSmallPosition.Val
            SEND_gNVM_u32RLMotorTemperature_Val: accessed-variable=gNVM_u32RLMotorTemperature.Val
            SEND_gNVM_u32RRMotorTemperature_Val: accessed-variable=gNVM_u32RRMotorTemperature.Val
            SEND_gNVM_u8FvMTripCntBlock_Val: accessed-variable=gNVM_u8FvMTripCntBlock.Val
            SEND_gNVM_u8PbcinDataStorageReadArea{1..3}_a_Val: accessed-variable=gNVM_u8PbcinDataStorageReadArea{1..3}_a.Val
            SEND_gNVM_u8SecOCBlock_Val: accessed-variable=gNVM_u8SecOCBlock.Val
            SEND_gNVM_u8SsminDataStorageRead_a_Val: accessed-variable=gNVM_u8SsminDataStorageRead_a.Val
  swc implementation Implementation_AppNvM_SR: behavior=AppNvM_SR
    code-descriptors:
      code Default: artifact-descriptors=autosar-engineering-object={short-label=Default, category=SWSRC}
package /DcmAppl_DID/DcmAppl_DID_dt
  impl type rt_Array_UInt8_6: category=ARRAY
    element rt_Array_UInt8_6: array-size=6, array-size-semantics=FIXED-SIZE, implementation-data-type=DcmAppl_DID_dt/UInt8
package /DcmAppl_DID/DcmAppl_DID_if
  sender receiver interface gAppDiag_1009: invalidation-policy{data-element=gAppDiag_1009/Val, handle-invalid=DONT-INVALIDATE}
    data Val: type=DcmAppl_DID_dt/rt_Array_UInt8_6
  sender receiver interface gAppDiag_1009Cnt: invalidation-policy{data-element=gAppDiag_1009Cnt/Val, handle-invalid=DONT-INVALIDATE}
    data Val: type=DcmAppl_DID_dt/UInt8
